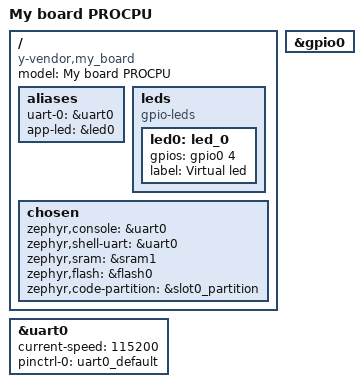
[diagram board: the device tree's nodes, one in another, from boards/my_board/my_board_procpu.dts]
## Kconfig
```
menuconfig LED_SUBSYSTEM
    bool "LED Subsystem"
    default y
    help
      Main menu for the LED subsystem.

if LED_SUBSYSTEM

    choice
        prompt "LED blink sleep time"
        default BLINK_SLEEP_1000MS

        config BLINK_SLEEP_250MS
            bool "250ms (very fast)"

        config BLINK_SLEEP_500MS
            bool "500ms (fast)"

        config BLINK_SLEEP_1000MS
            bool "1s (medium)"

        config BLINK_SLEEP_2000MS
            bool "2s (slow)"
    endchoice

    config BLINK_SLEEP_TIME_MS
        int
        default 250 if BLINK_SLEEP_250MS
        default 500 if BLINK_SLEEP_500MS
        default 1000 if BLINK_SLEEP_1000MS
        default 2000 if BLINK_SLEEP_2000MS

    menuconfig ADVANCED_LED_SETTINGS
        bool "Advanced LED settings"
        help
          Enable advanced configuration for brightness and fading.

    if ADVANCED_LED_SETTINGS

        config LED_BRIGHTNESS
            int "LED brightness (0-100)"
            default 100
            range 0 100
            help
              Set the brightness level from 0 to 100%.

        config LED_FADE_DURATION
            int "LED fade duration (ms)"
            default 500
            range 0 5000
            help
              Set the duration of the fade effect in ms.

        menu "Expert settings"
            visible if ADVANCED_LED_SETTINGS

            config ENABLE_LED_DEBUGGING
                bool "Enable LED debugging"
                default n

            config CUSTOM_BLINK_PATTERN
                bool "Custom blink pattern"
                default n
        endmenu

    endif # ADVANCED_LED_SETTINGS

endif # LED_SUBSYSTEM

source "Kconfig.zephyr"
```

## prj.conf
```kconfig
CONFIG_GPIO=y
CONFIG_LOG=y
CONFIG_ESP32_USE_UNSUPPORTED_REVISION=y

CONFIG_OUR_DRIVER=y

CONFIG_SHELL=y
```

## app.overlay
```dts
/ {
	aliases {
		app-led = &led0;
	};

	leds {
		compatible = "gpio-leds";
		led0: led_0 {
			gpios = <&gpio0 4 GPIO_ACTIVE_HIGH>;
			label = "Virtual led";
		};
	};

	our_driver0: our_driver {
		compatible = "our,driver";
		status = "okay";
	};
};
```

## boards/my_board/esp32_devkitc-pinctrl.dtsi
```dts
/*
 * Copyright (c) 2022-2025 Espressif Systems (Shanghai) Co., Ltd.
 *
 * SPDX-License-Identifier: Apache-2.0
 */

#include <zephyr/dt-bindings/pinctrl/esp-pinctrl-common.h>
#include <dt-bindings/pinctrl/esp32-pinctrl.h>
#include <zephyr/dt-bindings/pinctrl/esp32-gpio-sigmap.h>

&pinctrl {
	uart0_default: uart0_default {
		group1 {
			pinmux = <UART0_TX_GPIO1>;
			output-high;
		};
		group2 {
			pinmux = <UART0_RX_GPIO3>;
			bias-pull-up;
		};
	};
};
```

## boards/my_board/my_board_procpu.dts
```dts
/dts-v1/;

#include <espressif/esp32/esp32_wrover_e_n4r8.dtsi>
#include "esp32_devkitc-pinctrl.dtsi"
#include <espressif/partitions_0x1000_amp.dtsi>

/ {
	model = "My board PROCPU";
	compatible = "y-vendor,my_board";

	aliases {
		uart-0 = &uart0;
		app-led = &led0;
	};

	leds {
		compatible = "gpio-leds";
		led0: led_0 {
			gpios = <&gpio0 4 GPIO_ACTIVE_HIGH>;
			label = "Virtual led";
		};
	};

	chosen {
		zephyr,console = &uart0;
		zephyr,shell-uart = &uart0;
		zephyr,sram = &sram1;
		zephyr,flash = &flash0;
		zephyr,code-partition = &slot0_partition;
	};
};

&uart0 {
	status = "okay";
	current-speed = <115200>;
	pinctrl-0 = <&uart0_default>;
	pinctrl-names = "default";
};

&gpio0 {
	status = "okay";
};
```

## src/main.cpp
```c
#include <errno.h>
#include <zephyr/drivers/sensor.h>
#include <zephyr/device.h>
#include <zephyr/kernel.h>
#include <zephyr/logging/log.h>

LOG_MODULE_REGISTER(main, LOG_LEVEL_INF);

const struct device *driver = DEVICE_DT_GET(DT_NODELABEL(our_driver0));

int app_toggle_sensor() {
    static int current_state = 0;

    current_state = !current_state;
    LOG_INF("LED state: %s", current_state ? "ON" : "OFF");
    if(current_state) {
        // LED ON
        return sensor_sample_fetch_chan(driver, SENSOR_CHAN_AMBIENT_TEMP);
    } else {
        // LED OFF
        struct sensor_value val;
        return sensor_channel_get(driver, SENSOR_CHAN_AMBIENT_TEMP, &val);
    }
}

namespace debug {
    int test() {
        const struct device *driver = DEVICE_DT_GET(DT_NODELABEL(our_driver0));

        if(!device_is_ready(driver)) {
            return -ENODEV;
        }
        
        struct sensor_value val;
        auto ret = sensor_channel_get(driver, SENSOR_CHAN_AMBIENT_TEMP, &val);
        LOG_INF("MSG: Channel get %d", ret);

        ret = sensor_sample_fetch_chan(driver, SENSOR_CHAN_AMBIENT_TEMP);
        LOG_INF("MSG: Channel fetch %d", ret);
        
        return 0;
    }
}

int main()
{
    int ret;
    
/*
    if(ret = debug::test()) {
        LOG_INF("MSG: INIT_ERROR");
        return ret;
    }
*/
    if(!device_is_ready(driver)) {
        return -ENODEV;
    }

    while (1) {
        if ((ret = app_toggle_sensor()) != 0) {
            return ret;
        }
        k_msleep(CONFIG_APP_HEARTBEAT_PERIOD_MS);
    }
    return 0;
}
```
